VERSION ""

NS_ :

BS_:

BU_: XXX

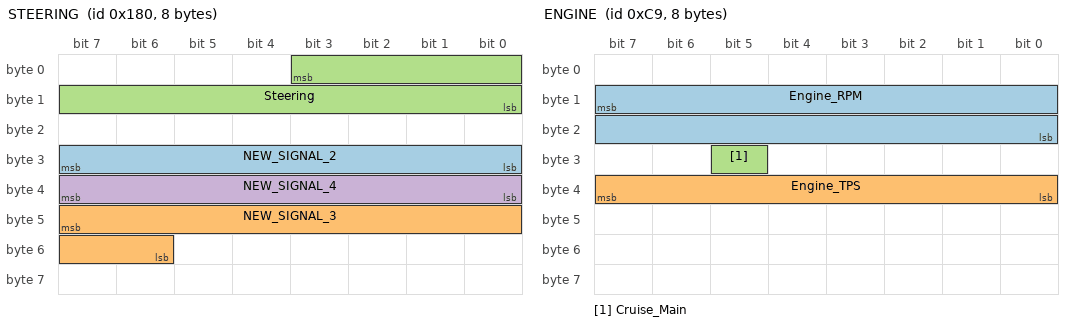
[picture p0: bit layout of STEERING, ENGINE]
BO_ 384 STEERING: 8 XXX
 SG_ NEW_SIGNAL_2 : 31|8@0- (1,0) [0|255] "" XXX
 SG_ NEW_SIGNAL_3 : 47|10@0- (1,0) [0|1023] "" XXX
 SG_ Steering : 3|12@0- (1,0) [0|4095] "" XXX
 SG_ NEW_SIGNAL_4 : 39|8@0- (1,0) [0|255] "" XXX

BO_ 201 ENGINE: 8 XXX
 SG_ Engine_RPM : 15|16@0+ (0.25,0) [0|65535] "RPM" XXX
 SG_ Engine_TPS : 39|8@0+ (0.392156863,0) [0|255] "" XXX
 SG_ Cruise_Main : 29|1@0+ (1,0) [0|1] "" XXX

BO_ 417 ACCELERATOR: 8 XXX
 SG_ Accelerator_Pedal : 55|8@0+ (1,0) [0|255] "" XXX

BO_ 401 Matches_Throttle: 8 XXX
 SG_ Throttle : 55|16@0+ (1,0) [0|65535] "" XXX

BO_ 640 NEW_MSG_1: 8 XXX
 SG_ NEW_SIGNAL_1 : 23|8@0+ (1,0) [0|255] "" XXX
